# DP32G030 register map
File version: 1.0
CPU: CM0 r0p0, little endian, no MPU, no FPU, 4 interrupt priority bits
Registers are 32-bit, read-write, reset 0x0 unless marked. A register's access mark holds for its fields unless they carry their own. Offsets are from the block's base; [hi:lo] are bit positions; {n}, {i} and the like mark numbered series.

## WWDT — WWDT unit
Base 0x4006A800
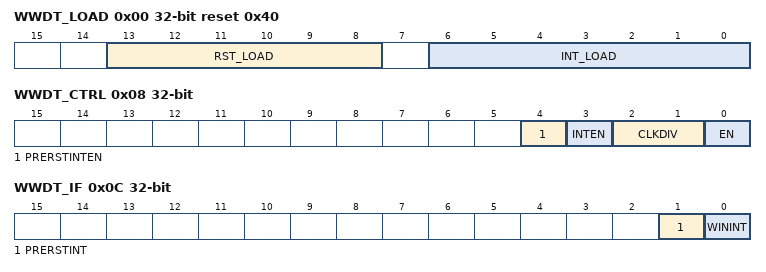
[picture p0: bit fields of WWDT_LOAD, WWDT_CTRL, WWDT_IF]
0x00 WWDT_LOAD reset 0x40 — WWDT initial value register
  [13:8] RST_LOAD — Window Reset Comparison Value Register Note 1: A reset can be generated when the watchdog counts down to the value Note 2: The watchdog can generate an interrupt when it counts down to this value plus one.
  [6:0] INT_LOAD — Window Interrupt Compare Value Register Note 1: When configuring, the window interrupt comparison value must be greater than the window reset comparison value. Note 2: The watchdog can generate an interrupt when it counts down to this value.
0x04 WWDT_VALUE ro reset 0x7F — WWDT Current count value register
  [6:0] VALUE — This register is a read-only register with a reset value of 0x7f. reading this register returns the current count value of the counter.
0x08 WWDT_CTRL — WWDT control register
  [4] PRERSTINTEN — Pre-reset interrupt enable bit 1: Enabling 0: Prohibited
  [3] INTEN — Window interrupt enable bit 1: Enabling 0: Prohibited
  [2:1] CLKDIV — Watchdog Counter Count Clock Prescaling 00: Watchdog count clock 1 division 01: Watchdog count clock 2 divisions 10: Watchdog Count Clock 4 divisions 11: Watchdog Count Clock 8 divisions Note: The watchdog count clock is a 4096 division of the system clock.
  [0] EN — WWDT start bit 1: Initiate WWDT counting 0: stop counting
0x0C WWDT_IF — WWDT Interrupt Status Register
  [1] PRERSTINT — Pre-reset interrupt flag bit (i.e. VALUE = RST_LOAD + 1)
  [0] WININT — Window interrupt flag bit (i.e., when VALUE = INT_LOAD), valid high
0x10 WWDT_FEED wo — WWDT feeding dog register
  [7:0] FEED — WWDT Restart Counter Registers Writing 0x55 to this register will restart the WWDT counter (dog feeding operation) Note: Feeding the dog will only take effect during the window period (INT_LOAD > VALUE > RST_LOAD), otherwise the dog feeding operation will generate a watchdog reset.

## PWM_BASE0 — PWM_BASE0 unit
Base 0x400B1000
0x00 PWMBASE0_EN — PWMBASE enable register
  [0] COUNTER_EN — PWMBASE Counter Enable Register When this bit is set to 1, it means that the counter starts counting, and CH0/CH1/CH2 will generate the PWM output waveform of the corresponding channel according to the pre-configured period value and comparison value. When this bit is configured to 0, it means the counter stops counting, and the output waveform level returns to the initial 0 level state after one full counting cycle.
0x04 PWMBASE0_DIV — PWMBASE Clock Prescaler Register
  [15:0] PWMBASE_DIV — PWMBASE Count Clock Prescaler Register 0x0000: indicates 1 division 0x0001: indicates 2 divisions 0x0002: Indicates 3 divisions ...... 0xFFFF: indicates 65536 division frequency
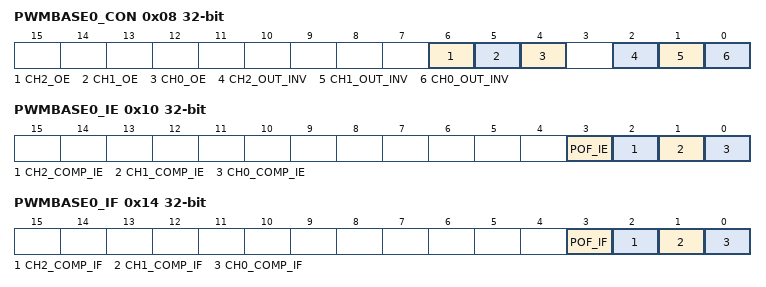
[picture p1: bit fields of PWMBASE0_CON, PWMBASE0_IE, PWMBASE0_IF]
0x08 PWMBASE0_CON — PWMBASE Output Configuration Register
  [6] CH2_OE — CH2 Channel waveform output enable 0: Output off, high resistance state on pin 1: Output CH2 square wave
  [5] CH1_OE — CH1 Channel waveform output enable 0: Output off, high resistance state on pin 1: Output CH1 square wave
  [4] CH0_OE — CH0 Channel waveform output enable 0: Output off, high resistance state on pin 1: Output CH0 square wave
  [2] CH2_OUT_INV — CH2 Output polarity flip-flop or not register 0: No change, CH2 output waveform is the original waveform 1: Polarity flip, CH2 output waveform is original waveform flip
  [1] CH1_OUT_INV — CH1 Output polarity flip-flop or not register 0: No change, CH1 output waveform is the original waveform 1: Polarity flip, CH1 output waveform is original waveform flip
  [0] CH0_OUT_INV — CH0 Output polarity flip-flop or not register 0: no change, CH0 output waveform is the original waveform 1: Polarity flip, CH0 output waveform is original waveform flip
0x0C PWMBASE0_PERIOD — PWMBASE Period configuration register
  [15:0] PWMx_PERIOD — PWMx Output Period Configuration Register The actual counting period is the value of the period configured for this register plus 1. Note 0: The period cannot be configured as 0. For example, if the configuration is decimal 199, the PWM waveform period is considered to be 200.
0x10 PWMBASE0_IE — PWMBASE interrupt enable register
  [3] POF_IE — Cycle overflow interrupt enable
  [2] CH2_COMP_IE — CH2 Reach flip point interrupt enable
  [1] CH1_COMP_IE — CH1 Reach flip point interrupt enable
  [0] CH0_COMP_IE — CH0 Reach flip point interrupt enable
0x14 PWMBASE0_IF — PWMBASE Interrupt Status Register
  [3] POF_IF write-1-clears — Cycle Overflow Interrupt Status Write 1 Clear
  [2] CH2_COMP_IF write-1-clears — CH2 Reach Flip Point Status Write 1 Clear
  [1] CH1_COMP_IF write-1-clears — CH1 Reach flip point status write 1 clear
  [0] CH0_COMP_IF write-1-clears — CH0 Reach flip point status write 1 clear
0x18 PWMBASE0_CNT ro reset 0xFFFF — PWMBASE Current count value register
  [15:0] PWMBASE_CNT — PWMBASE Counter Current Count Value Register
{0x20+0x10*i} PWMBASE0_CH{i}_COMP (i=0..2) — PWMBASE Channel {i} Flip Point Configuration Register
  [15:0] CH{i}_COMP — CH{i} Flip Point Configuration Register Note: If the count value is less than the rollover point value, output 1; if it is greater than or equal to the rollover point value, output 0.

## PWM_BASE1 — PWM_BASE1 unit
Base 0x400B1800
0x00 PWMBASE1_EN — PWMBASE enable register
  [0] COUNTER_EN — PWMBASE Counter Enable Register When this bit is set to 1, it means that the counter starts counting, and CH0/CH1/CH2 will generate the PWM output waveform of the corresponding channel according to the pre-configured period value and comparison value. When this bit is configured to 0, it means the counter stops counting, and the output waveform level returns to the initial 0 level state after one full counting cycle.
0x04 PWMBASE1_DIV — PWMBASE Clock Prescaler Register
  [15:0] PWMBASE_DIV — PWMBASE Count Clock Prescaler Register 0x0000: indicates 1 division 0x0001: indicates 2 divisions 0x0002: Indicates 3 divisions ...... 0xFFFF: indicates 65536 division frequency
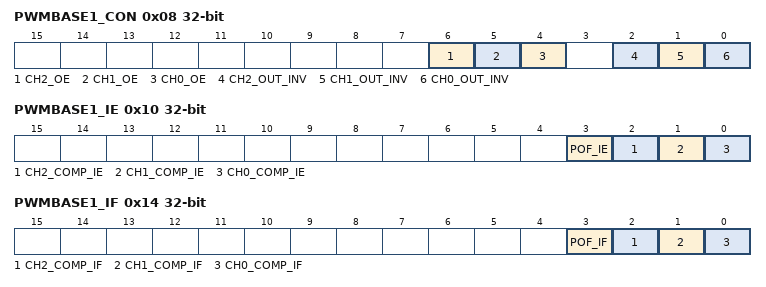
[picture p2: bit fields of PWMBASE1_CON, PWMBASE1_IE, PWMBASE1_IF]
0x08 PWMBASE1_CON — PWMBASE Output Configuration Register
  [6] CH2_OE — CH2 Channel waveform output enable 0: Output off, high resistance state on pin 1: Output CH2 square wave
  [5] CH1_OE — CH1 Channel waveform output enable 0: Output off, high resistance state on pin 1: Output CH1 square wave
  [4] CH0_OE — CH0 Channel waveform output enable 0: Output off, high resistance state on pin 1: Output CH0 square wave
  [2] CH2_OUT_INV — CH2 Output polarity flip-flop or not register 0: No change, CH2 output waveform is the original waveform 1: Polarity flip, CH2 output waveform is original waveform flip
  [1] CH1_OUT_INV — CH1 Output polarity flip-flop or not register 0: No change, CH1 output waveform is the original waveform 1: Polarity flip, CH1 output waveform is original waveform flip
  [0] CH0_OUT_INV — CH0 Output polarity flip-flop or not register 0: no change, CH0 output waveform is the original waveform 1: Polarity flip, CH0 output waveform is original waveform flip
0x0C PWMBASE1_PERIOD — PWMBASE Period configuration register
  [15:0] PWMx_PERIOD — PWMx Output Period Configuration Register The actual counting period is the value of the period configured for this register plus 1. Note 0: The period cannot be configured as 0. For example, if the configuration is decimal 199, the PWM waveform period is considered to be 200.
0x10 PWMBASE1_IE — PWMBASE interrupt enable register
  [3] POF_IE — Cycle overflow interrupt enable
  [2] CH2_COMP_IE — CH2 Reach flip point interrupt enable
  [1] CH1_COMP_IE — CH1 Reach flip point interrupt enable
  [0] CH0_COMP_IE — CH0 Reach flip point interrupt enable
0x14 PWMBASE1_IF — PWMBASE Interrupt Status Register
  [3] POF_IF write-1-clears — Cycle Overflow Interrupt Status Write 1 Clear
  [2] CH2_COMP_IF write-1-clears — CH2 Reach Flip Point Status Write 1 Clear
  [1] CH1_COMP_IF write-1-clears — CH1 Reach flip point status write 1 clear
  [0] CH0_COMP_IF write-1-clears — CH0 Reach flip point status write 1 clear
0x18 PWMBASE1_CNT ro reset 0xFFFF — PWMBASE Current count value register
  [15:0] PWMBASE_CNT — PWMBASE Counter Current Count Value Register
{0x20+0x10*i} PWMBASE1_CH{i}_COMP (i=0..2) — PWMBASE Channel {i} Flip Point Configuration Register
  [15:0] CH{i}_COMP — CH{i} Flip Point Configuration Register Note: If the count value is less than the rollover point value, output 1; if it is greater than or equal to the rollover point value, output 0.
